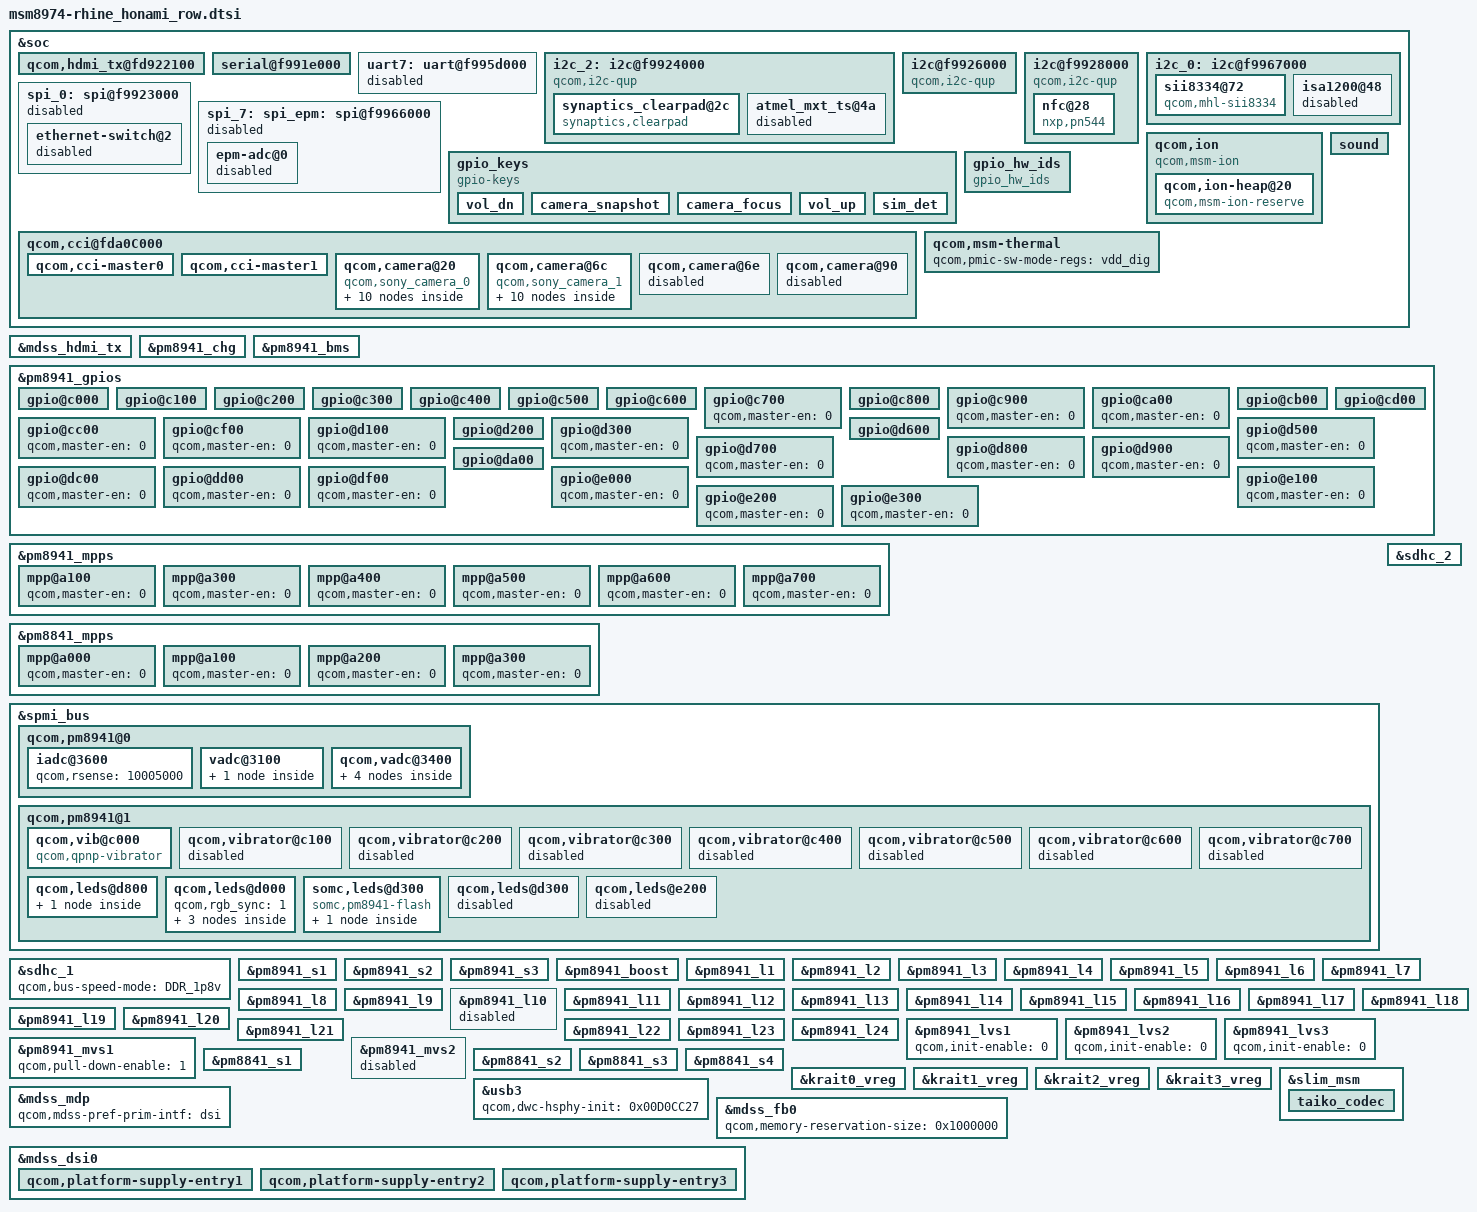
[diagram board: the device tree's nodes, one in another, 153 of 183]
/* arch/arm/boot/dts/msm8974-rhine_honami_row.dtsi
 *
 * Copyright (C) 2013-2014 Sony Mobile Communications AB.
 *
 * Author: Kouhei Fujiya <Kouhei.X.Fujiya@sonymobile.com>
 *
 * This program is free software; you can redistribute it and/or modify
 * it under the terms of the GNU General Public License version 2 and
 * only version 2 as published by the Free Software Foundation.
 *
 * This program is distributed in the hope that it will be useful,
 * but WITHOUT ANY WARRANTY; without even the implied warranty of
 * MERCHANTABILITY or FITNESS FOR A PARTICULAR PURPOSE.  See the
 * GNU General Public License for more details.
 */

/include/ "dsi-panel-honami.dtsi"

&soc {
	qcom,hdmi_tx@fd922100 {
		status = "ok";
	};

	/* BLSP2 */
	serial@f991e000 {
		status = "ok";
	};

	/* BLSP7 */
	uart7: uart@f995d000 {
		status = "disabled";
	};

	/* BLSP2 */
	i2c_2: i2c@f9924000 {
		cell-index = <0>;
		compatible = "qcom,i2c-qup";
		qcom,i2c-bus-freq = <355000>;
		qcom,scl-gpio = <&msmgpio 7 0x00>;
		qcom,sda-gpio = <&msmgpio 6 0x00>;
		status = "ok";
		synaptics_clearpad@2c {
			compatible = "synaptics,clearpad";
			reg = <0x2c>;
			interrupt-parent = <&msmgpio>;
			interrupts = <61 0x2>;
			touch_vdd-supply = <&pm8941_l22>;
			touch_vio-supply = <&pm8941_s3>;
			synaptics,irq_gpio = <&msmgpio 61 0x00>;
			num_sensor_rx = <28>;
			num_sensor_tx = <15>;
			pen_enabled = <0>;
			touch_pressure_enabled = <1>;
			touch_size_enabled = <0>;
			touch_orientation_enabled = <0>;
			preset_x_max = <1079>;
			preset_y_max = <1919>;
			preset_n_fingers = <10>;
			preset_n_bytes_per_object = <8>;
			por_delay_after = <200>;
		};

		atmel_mxt_ts@4a {
			status = "disabled";
		};
	};

	/* BLSP4 */
	i2c@f9926000 {
		cell-index = <1>;
		compatible = "qcom,i2c-qup";
		reg = <0xf9926000 0x1000>;
		#address-cells = <1>;
		#size-cells = <0>;
		reg-names = "qup_phys_addr";
		interrupts = <0 98 0>;
		interrupt-names = "qup_err_intr";
		qcom,i2c-bus-freq = <355000>;
		qcom,i2c-src-freq = <50000000>;
		qcom,master-id = <86>;
		status = "ok";
	};

	/* BLSP6 */
	i2c@f9928000 {
		cell-index = <2>;
		compatible = "qcom,i2c-qup";
		reg = <0xf9928000 0x1000>;
		#address-cells = <1>;
		#size-cells = <0>;
		reg-names = "qup_phys_addr";
		interrupts = <0 100 0>;
		interrupt-names = "qup_err_intr";
		qcom,i2c-bus-freq = <355000>;
		qcom,i2c-src-freq = <50000000>;
		qcom,master-id = <86>;
		status = "ok";
		nfc@28 {
			compatible = "nxp,pn544";
			reg = <0x28>;
			interrupt-parent = <&msmgpio>;
			interrupts = <59 0x0>;
			nxp,pvdd_en = <&msmgpio 76 0x00>;
			nxp,irq_gpio = <&msmgpio 59 0x00>;
			nxp,dwld_en = <&msmgpio 77 0x00>;
			nxp,ven = <&pm8941_gpios 23 0x01>;
			gpio_fwdl_enable = <0 0 0 2>;
			gpio_fwdl_disable = <0 0 1 0>;
		};
	};

	/* BLSP11 */
	i2c_0: i2c@f9967000 {
		cell-index = <4>;
		qcom,i2c-bus-freq = <355000>;
		status = "ok";
		sii8334@72 {
			compatible = "qcom,mhl-sii8334";
			reg = <0x72>;
			interrupt-parent = <&msmgpio>;
			interrupts = <64 0x2008>;
			mhl-intr-gpio = <&msmgpio 64 0>;
			mhl-pwr-gpio = <&msmgpio 60 0>;
			mhl-rst-gpio = <&msmgpio 16 0>;
			qcom,hdmi-tx-map = <&mdss_hdmi_tx>;
		};

		isa1200@48 {
			status = "disabled";
		};
	};

	/* BLSP1 */
	spi_0: spi@f9923000 {
		status = "disabled";

		ethernet-switch@2 {
			status = "disabled";
		};
	};

	/* BLSP10 */
	spi_7: spi_epm: spi@f9966000 {
		status = "disabled";

		epm-adc@0 {
			status = "disabled";
		};
	};

	gpio_keys {
		compatible = "gpio-keys";
		input-name = "gpio-keys";
		interrupt-parent = <&msmgpio>;
		interrupts = <9 0>;

		vol_dn {
			label = "volume_down";
			gpios = <&pm8941_gpios 2 0x1>;
			linux,input-type = <1>;
			linux,code = <114>;
			gpio-key,wakeup;
			debounce-interval = <15>;
		};

		camera_snapshot {
			label = "camera_snapshot";
			gpios = <&pm8941_gpios 3 0x1>;
			linux,input-type = <1>;
			linux,code = <0x2fe>;
			gpio-key,wakeup;
			debounce-interval = <15>;
		};

		camera_focus {
			label = "camera_focus";
			gpios = <&pm8941_gpios 4 0x1>;
			linux,input-type = <1>;
			linux,code = <0x210>;
			gpio-key,wakeup;
			debounce-interval = <15>;
		};

		vol_up {
			label = "volume_up";
			gpios = <&pm8941_gpios 5 0x1>;
			linux,input-type = <1>;
			linux,code = <115>;
			gpio-key,wakeup;
			debounce-interval = <15>;
		};

		sim_det {
			label = "sim-detection";
			gpios = <&msmgpio 9 0x0>;
			linux,input-type = <5>;
			linux,code = <7>;
			gpio-key,wakeup;
			debounce-interval = <10>;
		};
	};

	qcom,cci@fda0C000 {
		qcom,cci-master0 {
			qcom,hw-thigh = <22>;
			qcom,hw-tlow = <33>;
		};

		qcom,cci-master1 {
			qcom,hw-thigh = <22>;
			qcom,hw-tlow = <33>;
		};

		qcom,camera@20 {
			compatible = "qcom,sony_camera_0";
			reg = <0x20 0x0>;
			status = "ok";
			qcom,slave-id = <0x20 0x0 0x0000>;
			qcom,csiphy-sd-index = <0>;
			qcom,csid-sd-index = <0>;
			qcom,mount-angle = <270>;
			qcom,sensor-name = "sony_camera_0";
			cam_vdig-supply = <&pm8941_l3>;
			cam_vana-supply = <&pm8941_l17>;
			cam_vio-supply = <&pm8941_lvs2>;
			cam_vaf-supply = <&pm8941_l23>;
			qcom,cam-vreg-name = "cam_vdig", "cam_vana", "cam_vio",
					     "cam_vaf";
			qcom,cam-vreg-type = <0 0 1 0>;
			qcom,cam-vreg-min-voltage = <1200000 2700000 0 2800000>;
			qcom,cam-vreg-max-voltage = <1200000 2700000 0 2800000>;
			qcom,cam-vreg-op-mode = <105000 85600 0 300000>;
			qcom,gpio-no-mux = <0>;
			gpios = <&msmgpio 15 0>,
				<&msmgpio 94 0>;
			qcom,gpio-reset = <1>;
			qcom,gpio-req-tbl-num = <0 1>;
			qcom,gpio-req-tbl-flags = <1 0>;
			qcom,gpio-req-tbl-label = "CAMIF_MCLK",
						  "CAM_RESET1";
			qcom,gpio-set-tbl-num = <1 1>;
			qcom,gpio-set-tbl-flags = <0 2>;
			qcom,gpio-set-tbl-delay = <1 1000>;
			qcom,csi-lane-assign = <0x4320>;
			qcom,csi-lane-mask = <0x1F>;
			qcom,sensor-position = <0>;
			qcom,sensor-mode = <1>;
			qcom,cci-master = <0>;
			sony,i2c_addr = <0x20>;
			sony,eeprom_addr = <0xA0>;
			sony,eeprom_type = <0>;
			sony,eeprom_max_len = <2048>;
			sony,gpio_af = <0>;
			sony,subdev_code = <0x3007>;

			sony,camera_modules {
				module_names = "GENERIC", "SOI20BS0",
						"SOI08BS2";
				default_module_name = "SOI20BS0";

				GENERIC {
					mount_angle = <270>;
					sensor_rotation = <180>;
					sensor_facing = <0>;
					has_3a = <0>;
					pll_num = <18>;
					pll = <600 318 386 684 318 578 293 600 597 599 318 596 599 474 599 825 578 578>;
					power_off {
						commands =
								"I2C_WRITE",
								"GPIO_RESET",
								"CAM_CLK",
								"CAM_VAF",
								"CAM_VANA",
								"CAM_VIO",
								"CAM_VDIG",
								"EXIT";
						CAM_VDIG =
							<0 0xFFFFFFFF 0 15>;
						CAM_VIO = <1 0xFFFFFFFF 0 1>;
						CAM_VANA =
							<2 0xFFFFFFFF 0 1>;
						CAM_VAF = <3 0xFFFFFFFF 0 0>;
						GPIO_RESET = <5 0x0 0 1>;
						CAM_CLK = <6 0xFFFFFFFF 0 1>;
						I2C_WRITE = <7 0x0100 0 100>;
						EXIT = <8 0x0 0 0>;
					};
					power_on {
						commands =
								"CAM_VDIG",
								"CAM_VIO",
								"CAM_VANA",
								"CAM_VAF",
								"GPIO_RESET",
								"CAM_CLK",
								"EXIT";
						CAM_VDIG = <0 1200 85000 1>;
						CAM_VIO = <1 0 0 1>;
						CAM_VANA = <2 2700 103000 0>;
						CAM_VAF = <3 2800 106500 2>;
						GPIO_RESET = <5 1 0 1>;
						CAM_CLK = <6 0 0 1>;
						EXIT = <8 0x0 0 0>;
					};
				};
				SOI20BS0 {
					mount_angle = <90>;
					sensor_rotation = <0>;
					sensor_facing = <0>;
					has_3a = <0>;
					pll_num = <18>;
					pll = <600 318 386 684 318 578 293 600 597 599 318 596 599 474 599 825 578 578>;
					power_off {
						commands =
								"I2C_WRITE",
								"GPIO_RESET",
								"CAM_CLK",
								"CAM_VAF",
								"CAM_VANA",
								"CAM_VIO",
								"CAM_VDIG",
								"EXIT";
						CAM_VDIG =
							<0 0xFFFFFFFF 0 15>;
						CAM_VIO = <1 0xFFFFFFFF 0 1>;
						CAM_VANA =
							<2 0xFFFFFFFF 0 1>;
						CAM_VAF = <3 0xFFFFFFFF 0 0>;
						GPIO_RESET = <5 0x0 0 1>;
						CAM_CLK = <6 0xFFFFFFFF 0 1>;
						I2C_WRITE = <7 0x0100 0 100>;
						EXIT = <8 0x0 0 0>;
					};
					power_on {
						commands =
								"CAM_VDIG",
								"CAM_VIO",
								"CAM_VANA",
								"CAM_VAF",
								"GPIO_RESET",
								"CAM_CLK",
								"EXIT";
						CAM_VDIG = <0 1200 85000 1>;
						CAM_VIO = <1 0 0 1>;
						CAM_VANA = <2 2700 103000 0>;
						CAM_VAF = <3 2800 106500 2>;
						GPIO_RESET = <5 1 0 1>;
						CAM_CLK = <6 0 0 1>;
						EXIT = <8 0x0 0 0>;
					};
				};
				SOI08BS2 {
					mount_angle = <270>;
					sensor_rotation = <180>;
					sensor_facing = <0>;
					has_3a = <0>;
					pll_num = <18>;
					pll = <674 674 674 674 674 674 674 674 674 674 674 674 674 674 674 674 674 674>;
					power_off {
						commands =
								"I2C_WRITE",
								"GPIO_RESET",
								"CAM_CLK",
								"CAM_VAF",
								"CAM_VANA",
								"CAM_VIO",
								"CAM_VDIG",
								"EXIT";
						CAM_VDIG =
							<0 0xFFFFFFFF 0 15>;
						CAM_VIO = <1 0xFFFFFFFF 0 1>;
						CAM_VANA =
							<2 0xFFFFFFFF 0 1>;
						CAM_VAF = <3 0xFFFFFFFF 0 0>;
						GPIO_RESET = <5 0x0 0 1>;
						CAM_CLK = <6 0xFFFFFFFF 0 1>;
						I2C_WRITE = <7 0x0100 0 100>;
						EXIT = <8 0x0 0 0>;
					};
					power_on {
						commands =
								"CAM_VDIG",
								"CAM_VIO",
								"CAM_VANA",
								"CAM_VAF",
								"GPIO_RESET",
								"CAM_CLK",
								"EXIT";
						CAM_VDIG = <0 1200 85000 1>;
						CAM_VIO = <1 0 0 1>;
						CAM_VANA = <2 2700 103000 0>;
						CAM_VAF = <3 2800 106500 2>;
						GPIO_RESET = <5 1 0 1>;
						CAM_CLK = <6 0 0 1>;
						EXIT = <8 0x0 0 0>;
					};
				};
			};
		};

		qcom,camera@6c {
			compatible = "qcom,sony_camera_1";
			reg = <0x6c 0x0>;
			status = "ok";
			qcom,slave-id = <0x6c 0x0000 0x0000>;
			qcom,csiphy-sd-index = <2>;
			qcom,csid-sd-index = <2>;
			qcom,mount-angle = <270>;
			qcom,sensor-name = "sony_camera_1";
			cam_vdig-supply = <&pm8941_l3>;
			cam_vana-supply = <&pm8941_l17>;
			cam_vio-supply = <&pm8941_lvs2>;
			qcom,cam-vreg-name = "cam_vdig", "cam_vana", "cam_vio";
			qcom,cam-vreg-type = <0 0 1>;
			qcom,cam-vreg-min-voltage = <1200000 2700000 0>;
			qcom,cam-vreg-max-voltage = <1200000 2700000 0>;
			qcom,cam-vreg-op-mode = <105000 85600 0>;
			qcom,gpio-no-mux = <0>;
			gpios = <&msmgpio 17 0>,
				<&msmgpio 18 0>;
			qcom,gpio-reset = <1>;
			qcom,gpio-req-tbl-num = <0 1>;
			qcom,gpio-req-tbl-flags = <1 0>;
			qcom,gpio-req-tbl-label = "CAMIF_MCLK",
						  "CAM_RESET1";
			qcom,gpio-set-tbl-num = <1 1>;
			qcom,gpio-set-tbl-flags = <0 2>;
			qcom,gpio-set-tbl-delay = <1 1000>;
			qcom,csi-lane-assign = <0x4320>;
			qcom,csi-lane-mask = <0x7>;
			qcom,sensor-position = <1>;
			qcom,sensor-mode = <1>;
			qcom,cci-master = <1>;
			sony,i2c_addr = <0x6c>;
			sony,eeprom_addr = <0xA0>;
			sony,eeprom_type = <0>;
			sony,eeprom_max_len = <1024>;
			sony,gpio_af = <0>;
			sony,subdev_code = <0x3007>;

			sony,camera_modules {
				module_names = "GENERIC", "LGI02BN1",
						"SEM02BN1";
				default_module_name = "SEM02BN1";

				GENERIC {
					mount_angle = <270>;
					sensor_rotation = <180>;
					sensor_facing = <1>;
					has_3a = <0>;
					pll_num = <18>;
					pll = <101 101 101 101 101 101 101 101 101 101 101 101 101 101 101 101 101 101>;
					power_off {
						commands =
								"I2C_WRITE",
								"GPIO_RESET",
								"CAM_CLK",
								"CAM_VANA",
								"CAM_VIO",
								"CAM_VDIG",
								"EXIT";
						CAM_VDIG =
							<0 0xFFFFFFFF 0 1>;
						CAM_VIO = <1 0xFFFFFFFF 0 1>;
						CAM_VANA =
							<2 0xFFFFFFFF 0 1>;
						GPIO_RESET = <5 0x0 0 1>;
						CAM_CLK = <6 0xFFFFFFFF 0 1>;
						I2C_WRITE = <7 0x0100 0 100>;
						EXIT = <8 0x0 0 0>;
					};
					power_on {
						commands =
								"CAM_VDIG",
								"CAM_VIO",
								"CAM_VANA",
								"GPIO_RESET",
								"CAM_CLK",
								"EXIT";
						CAM_VDIG = <0 1200 85000 1>;
						CAM_VIO = <1 0 0 1>;
						CAM_VANA = <2 2700 103000 1>;
						GPIO_RESET = <5 1 0 1>;
						CAM_CLK = <6 0 0 1>;
						EXIT = <8 0x0 0 0>;
					};
				};
				LGI02BN1 {
					mount_angle = <270>;
					sensor_rotation = <180>;
					sensor_facing = <1>;
					has_3a = <0>;
					pll_num = <18>;
					pll = <101 101 101 101 101 101 101 101 101 101 101 101 101 101 101 101 101 101>;
					power_off {
						commands =
								"I2C_WRITE",
								"GPIO_RESET",
								"CAM_CLK",
								"CAM_VANA",
								"CAM_VIO",
								"CAM_VDIG",
								"EXIT";
						CAM_VDIG =
							<0 0xFFFFFFFF 0 1>;
						CAM_VIO = <1 0xFFFFFFFF 0 1>;
						CAM_VANA =
							<2 0xFFFFFFFF 0 1>;
						GPIO_RESET = <5 0x0 0 1>;
						CAM_CLK = <6 0xFFFFFFFF 0 1>;
						I2C_WRITE = <7 0x0100 0 100>;
						EXIT = <8 0x0 0 0>;
					};
					power_on {
						commands =
								"CAM_VDIG",
								"CAM_VIO",
								"CAM_VANA",
								"GPIO_RESET",
								"CAM_CLK",
								"EXIT";
						CAM_VDIG = <0 1200 85000 1>;
						CAM_VIO = <1 0 0 1>;
						CAM_VANA = <2 2700 103000 1>;
						GPIO_RESET = <5 1 0 1>;
						CAM_CLK = <6 0 0 1>;
						EXIT = <8 0x0 0 0>;
					};
				};
				SEM02BN1 {
					mount_angle = <270>;
					sensor_rotation = <180>;
					sensor_facing = <1>;
					has_3a = <0>;
					pll_num = <18>;
					pll = <101 101 101 101 101 101 101 101 101 101 101 101 101 101 101 101 101 101>;
					power_off {
						commands =
								"I2C_WRITE",
								"GPIO_RESET",
								"CAM_CLK",
								"CAM_VANA",
								"CAM_VIO",
								"CAM_VDIG",
								"EXIT";
						CAM_VDIG =
							<0 0xFFFFFFFF 0 1>;
						CAM_VIO = <1 0xFFFFFFFF 0 1>;
						CAM_VANA =
							<2 0xFFFFFFFF 0 1>;
						GPIO_RESET = <5 0x0 0 1>;
						CAM_CLK = <6 0xFFFFFFFF 0 1>;
						I2C_WRITE = <7 0x0100 0 100>;
						EXIT = <8 0x0 0 0>;
					};
					power_on {
						commands =
								"CAM_VDIG",
								"CAM_VIO",
								"CAM_VANA",
								"GPIO_RESET",
								"CAM_CLK",
								"EXIT";
						CAM_VDIG = <0 1200 85000 1>;
						CAM_VIO = <1 0 0 1>;
						CAM_VANA = <2 2700 103000 1>;
						GPIO_RESET = <5 1 0 1>;
						CAM_CLK = <6 0 0 1>;
						EXIT = <8 0x0 0 0>;
					};
				};
			};
		};

		/* disable Qualcomm camera sensors */
		qcom,camera@6e {
			status = "disabled";
		};

		qcom,camera@90 {
			status = "disabled";
		};
	};

	qcom,ion {
		compatible = "qcom,msm-ion";

		qcom,ion-heap@20 { /* CAMERA HEAP */
			compatible = "qcom,msm-ion-reserve";
			reg = <20>;
			qcom,heap-align = <0x1000>;
			qcom,memory-reservation-type = "EBI1"; /* reserve EBI memory */
			qcom,memory-reservation-size = <0x6400000>;
			qcom,ion-heap-type = "CARVEOUT";
		};
	};

	sound {
		qcom,audio-routing =
			"RX_BIAS", "MCLK",
			"LDO_H", "MCLK",
			"Ext Spk Bottom Pos", "LINEOUT1",
			"Ext Spk Bottom Neg", "LINEOUT3",
			"Ext Spk Top Pos", "LINEOUT2",
			"Ext Spk Top Neg", "LINEOUT4",
			"AMIC1", "MIC BIAS1 External",
			"MIC BIAS1 External", "Handset Mic",
			"AMIC2", "MIC BIAS2 External",
			"MIC BIAS2 External", "Headset Mic",
			"AMIC3", "MIC BIAS3 External",
			"MIC BIAS3 External", "ANCLeft Headset Mic",
			"AMIC4", "MIC BIAS1 External",
			"MIC BIAS1 External", "Handset Mic",
			"AMIC5", "MIC BIAS1 External",
			"MIC BIAS1 External", "Secondary Mic",
			"AMIC6", "MIC BIAS4 External",
			"MIC BIAS4 External", "Handset FB ANC Mic";
	};

	gpio_hw_ids {
		compatible = "gpio_hw_ids";

		gpios = <&pm8941_gpios 1 0>,
			<&pm8941_gpios 6 0>,
			<&pm8941_gpios 7 0>,
			<&pm8941_gpios 14 0>;
	};

	qcom,msm-thermal {
		qcom,pmic-sw-mode-regs = "vdd_dig";
	};
};

&mdss_hdmi_tx {
	/* rhine doesn't use hpd-5v */
	qcom,hdmi-tx-supply-names = "hpd-gdsc", "core-vdda", "core-vcc";
	qcom,hdmi-tx-min-voltage-level = <0 1800000 1800000>;
	qcom,hdmi-tx-max-voltage-level = <0 1800000 1800000>;
	qcom,hdmi-tx-peak-current = <0 300000 0>;
};

&pm8941_chg {
	qcom,vddmax-mv = <4350>;
	qcom,vddsafe-mv = <4400>;
	qcom,ibatmax-ma = <1500>;
	qcom,ibatterm-ma = <150>;
	qcom,ibatsafe-ma = <1500>;
	qcom,maxinput-dc-ma = <1800>;
	qcom,maxinput-usb-ma = <1500>;
	qcom,cool-bat-mv = <4350>;
	qcom,ibatmax-warm-ma = <900>;
	qcom,warm-bat-mv = <4200>;
	qcom,ibatmax-cool-ma = <900>;
	qcom,vbatdet-delta-mv = <20>;
	qcom,vbatdet-delta-soc = <1>;
	qcom,thermal-mitigation = <1500 1500 1100 900 700 500 300 200 100 0>;
	qcom,tchg-mins = <512>;
};

&pm8941_bms {
	qcom,r-sense-uohm = <10005>;
	qcom,v-cutoff-uv = <3200000>;
	qcom,max-voltage-uv = <4350000>;
	qcom,r-conn-mohm = <0>;
	qcom,low-soc-calculate-soc-threshold = <5>;
	qcom,low-soc-calculate-soc-ms = <1000>;
	qcom,calculate-soc-ms = <30000>;
	qcom,chg-term-ua = <150000>;
	qcom,use-external-rsense = <1>;
	qcom,batt-type = <3>;
	qcom,shutdown-soc-valid-limit = <40>;
	qcom,clamp-soc-max-count = <2>;
	qcom,fcc-resolution = <13>;
};

&pm8941_gpios {
	/* GPIO_1: HW_ID_0 */
	gpio@c000 {
		qcom,src-sel = <0>;		/* GPIO */
		qcom,mode = <0>;		/* In */
		qcom,vin-sel = <2>;		/* S3 */
		qcom,pull = <5>;		/* NP */
		qcom,master-en = <1>;		/* Enable */
		status = "ok";
	};

	/* GPIO_2: VOL_DN */
	gpio@c100 {
		qcom,src-sel = <0>;		/* GPIO */
		qcom,mode = <0>;		/* In */
		qcom,vin-sel = <2>;		/* S3 */
		qcom,pull = <0>;		/* PU */
		qcom,master-en = <1>;		/* Enable */
		status = "ok";
	};

	/* GPIO_3: SNAPSHOT */
	gpio@c200 {
		qcom,src-sel = <0>;		/* GPIO */
		qcom,mode = <0>;		/* In */
		qcom,vin-sel = <2>;		/* S3 */
		qcom,pull = <0>;		/* PU */
		qcom,master-en = <1>;		/* Enable */
		status = "ok";
	};

	/* GPIO_4: FOCUS */
	gpio@c300 {
		qcom,src-sel = <0>;		/* GPIO */
		qcom,mode = <0>;		/* In */
		qcom,vin-sel = <2>;		/* S3 */
		qcom,pull = <0>;		/* PU */
		qcom,master-en = <1>;		/* Enable */
		status = "ok";
	};

	/* GPIO_5: VOL_UP */
	gpio@c400 {
		qcom,src-sel = <0>;		/* GPIO */
		qcom,mode = <0>;		/* In */
		qcom,vin-sel = <2>;		/* S3 */
		qcom,pull = <0>;		/* PU */
		qcom,master-en = <1>;		/* Enable */
		status = "ok";
	};

	/* GPIO_6: HW_ID_1 */
	gpio@c500 {
		qcom,src-sel = <0>;		/* GPIO */
		qcom,mode = <0>;		/* In */
		qcom,vin-sel = <2>;		/* S3 */
		qcom,pull = <5>;		/* NP */
		qcom,master-en = <1>;		/* Enable */
		status = "ok";
	};

	/* GPIO_7: HW_ID_2 */
	gpio@c600 {
		qcom,src-sel = <0>;		/* GPIO */
		qcom,mode = <0>;		/* In */
		qcom,vin-sel = <2>;		/* S3 */
		qcom,pull = <5>;		/* NP */
		qcom,master-en = <1>;		/* Enable */
		status = "ok";
	};

	/* GPIO_8: NC */
	gpio@c700 {
		qcom,master-en = <0>;		/* Disable */
		status = "ok";
	};

	/* GPIO_9: RF_ID_EN */
	gpio@c800 {
		qcom,src-sel = <0>;		/* GPIO */
		qcom,mode = <1>;		/* Out */
		qcom,output-type = <0>;		/* CMOS */
		qcom,vin-sel = <2>;		/* S3 */
		qcom,out-strength = <3>;	/* High */
		qcom,invert = <0>;		/* Low */
		qcom,master-en = <1>;		/* Enable */
		status = "ok";
	};

	/* GPIO_10: NC (FCHG_CNT) */
	gpio@c900 {
		qcom,master-en = <0>;		/* Disable */
		status = "ok";
	};

	/* GPIO_11: NC (AUD_DSP_PWR_EN) */
	gpio@ca00 {
		qcom,master-en = <0>;		/* Disable */
		status = "ok";
	};

	/* GPIO_12: RF_ID_EXTENTION */
	gpio@cb00 {
		qcom,src-sel = <0>;		/* GPIO */
		qcom,mode = <0>;		/* In */
		qcom,vin-sel = <2>;		/* S3 */
		qcom,pull = <4>;		/* PD */
		qcom,master-en = <1>;		/* Enable */
		status = "ok";
	};

	/* GPIO_13: NC (TUNER_STATUS0) */
	gpio@cc00 {
		qcom,master-en = <0>;		/* Disable */
		status = "ok";
	};

	/* GPIO_14: HW_ID_3 */
	gpio@cd00 {
		qcom,src-sel = <0>;		/* GPIO */
		qcom,mode = <0>;		/* In */
		qcom,vin-sel = <2>;		/* S3 */
		qcom,pull = <4>;		/* PD */
		qcom,master-en = <1>;		/* Enable */
		status = "ok";
	};

	/* GPIO_15: DIVCLK1_CODEC */
	/* Follow QCT */

	/* GPIO_16: NC */
	gpio@cf00 {
		qcom,master-en = <0>;		/* Disable */
		status = "ok";
	};

	/* GPIO_17: (DIVCLK3) QPA_XO */
	/* Follow QCT */

	/* GPIO_18: NC (TUNER_STATUS1) */
	gpio@d100 {
		qcom,master-en = <0>;		/* Disable */
		status = "ok";
	};

	/* GPIO_19: DISP_RESET_N */
	gpio@d200 {
		qcom,src-sel = <0>;		/* GPIO */
		qcom,mode = <1>;		/* Out */
		qcom,output-type = <0>;		/* CMOS */
		qcom,vin-sel = <2>;		/* S3 */
		qcom,out-strength = <1>;	/* Low */
		qcom,invert = <0>;		/* Low */
		qcom,master-en = <1>;		/* Enable */
		status = "ok";
	};

	/* GPIO_20: NC (IR_LEVEL_EN) */
	gpio@d300 {
		qcom,master-en = <0>;		/* Disable */
		status = "ok";
	};

	/* GPIO_21: BOOST_BYP_EN */
	/* Follow QCT */

	/* GPIO_22: NC (HS_DET) */
	gpio@d500 {
		qcom,master-en = <0>;		/* Disable */
		status = "ok";
	};

	/* GPIO_23: NFC_VEN */
	gpio@d600 {
		qcom,src-sel = <0>;		/* GPIO */
		qcom,mode = <1>;		/* Out */
		qcom,output-type = <0>;		/* CMOS */
		qcom,vin-sel = <2>;		/* S3 */
		qcom,out-strength = <1>;	/* Low */
		qcom,invert = <1>;		/* High */
		qcom,master-en = <1>;		/* Enable */
		status = "ok";
	};

	/* GPIO_24: NC (NFC_EXT_LDO_EN) */
	gpio@d700 {
		qcom,master-en = <0>;		/* Disable */
		status = "ok";
	};

	/* GPIO_25: NC (IR_RESET) */
	gpio@d800 {
		qcom,master-en = <0>;		/* Disable */
		status = "ok";
	};

	/* GPIO_26: NC (TUNER_ANT_SW_EN) */
	gpio@d900 {
		qcom,master-en = <0>;		/* Disable */
		status = "ok";
	};

	/* GPIO_27: FLASH_LED_NOW */
	gpio@da00 {
		qcom,src-sel = <2>;		/* Alternate function 1 */
		qcom,mode = <0>;		/* In */
		qcom,vin-sel = <2>;		/* S3 */
		qcom,pull = <4>;		/* PD */
		qcom,master-en = <1>;		/* Enable */
		status = "ok";
	};

	/* GPIO_28: TX_GTR_THRES */
	/* Follow QCT */

	/* GPIO_29: NC */
	gpio@dc00 {
		qcom,master-en = <0>;		/* Disable */
		status = "ok";
	};

	/* GPIO_30: NC */
	gpio@dd00 {
		qcom,master-en = <0>;		/* Disable */
		status = "ok";
	};

	/* GPIO_31: BATT_REM_ALERM */
	/* Follow QCT */

	/* GPIO_32: NC (TUNER_ANT_SW1) */
	gpio@df00 {
		qcom,master-en = <0>;		/* Disable */
		status = "ok";
	};

	/* GPIO_33: NC (FELICA_FF) */
	gpio@e000 {
		qcom,master-en = <0>;		/* Disable */
		status = "ok";
	};

	/* GPIO_34: NC (FELICA_LOCK) */
	gpio@e100 {
		qcom,master-en = <0>;		/* Disable */
		status = "ok";
	};

	/* GPIO_35: NC (Reserved for ANC_HS_DET) */
	gpio@e200 {
		qcom,master-en = <0>;		/* Disable */
		status = "ok";
	};

	/* GPIO_36: NC */
	gpio@e300 {
		qcom,master-en = <0>;		/* Disable */
		status = "ok";
	};
};

&pm8941_mpps {
	/* MPP_1: SDC_UIM_VBIAS */
	/* Follow QCT */

	/* MPP_2: NC */
	mpp@a100 {
		qcom,master-en = <0>;		/* Disable */
		status = "ok";
	};

	/* MPP_3: TXDAC0_VREF */
	/* Follow QCT */

	/* MPP_4: NC */
	mpp@a300 {
		qcom,master-en = <0>;		/* Disable */
		status = "ok";
	};

	/* MPP_5: NC */
	mpp@a400 {
		qcom,master-en = <0>;		/* Disable */
		status = "ok";
	};

	/* MPP_6: NC (ACC_ADC) */
	mpp@a500 {
		qcom,master-en = <0>;		/* Disable */
		status = "ok";
	};

	/* MPP_7: RF_ID */
	mpp@a600 {
		qcom,master-en = <0>;		/* Disable */
		status = "ok";
	};

	/* MPP_8: NC */
	mpp@a700 {
		qcom,master-en = <0>;		/* Disable */
		status = "ok";
	};
};

&pm8841_mpps {
	/* MPP_1: NC (LMU_EN) */
	mpp@a000 {
		qcom,master-en = <0>;		/* Disable */
		status = "ok";
	};

	/* MPP_2: NC (FLASH_DR_RST_N) */
	mpp@a100 {
		qcom,master-en = <0>;		/* Disable */
		status = "ok";
	};

	/* MPP_3: NC */
	mpp@a200 {
		qcom,master-en = <0>;		/* Disable */
		status = "ok";
	};

	/* MPP_4: NC */
	mpp@a300 {
		qcom,master-en = <0>;		/* Disable */
		status = "ok";
	};
};

&spmi_bus {
	qcom,pm8941@0 {
		iadc@3600 {
			qcom,rsense = <10005000>;
		};
	};

	qcom,pm8941@1 {
		qcom,vib@c000 {
			status = "okay";
			compatible = "qcom,qpnp-vibrator";
			reg = <0xc000 0x100>;
			label = "vibrator";
			qcom,qpnp-vib-vtg-level-mV = <3100>;
		};

		qcom,vibrator@c100 {
			status = "disabled";
		};

		qcom,vibrator@c200 {
			status = "disabled";
		};

		qcom,vibrator@c300 {
			status = "disabled";
		};

		qcom,vibrator@c400 {
			status = "disabled";
		};

		qcom,vibrator@c500 {
			status = "disabled";
		};

		qcom,vibrator@c600 {
			status = "disabled";
		};

		qcom,vibrator@c700 {
			status = "disabled";
		};

		qcom,leds@d800 {
			status = "okay";
			qcom,wled_0 {
				label = "wled";
				linux,name = "wled:backlight";
				linux,default-trigger = "bkl-trigger";
				qcom,cs-out-en = <1>;
				qcom,cabc-en = <1>;
				qcom,op-fdbck = <0>;
				qcom,default-state = "on";
				qcom,max-current = <20>;
				qcom,ctrl-delay-us = <0>;
				qcom,boost-curr-lim = <3>;
				qcom,cp-sel = <0>;
				qcom,switch-freq = <2>;
				qcom,ovp-val = <2>;
				qcom,num-strings = <2>;
				qcom,id = <0>;
			};
		};

		qcom,leds@d000 {
			status = "okay";
			qcom,rgb_sync = <1>;

			qcom,rgb_0 {
				label = "rgb";
				linux,name = "led:rgb_red";
				qcom,mode = "pwm";
				qcom,pwm-channel = <6>;
				qcom,pwm-us = <1000>;
				qcom,pwm-max-value = <304>;
				qcom,max-current = <12>;
				qcom,default-state = "off";
				qcom,id = <3>;
				linux,default-trigger = "none";
			};

			qcom,rgb_1 {
				label = "rgb";
				linux,name = "led:rgb_green";
				qcom,mode = "pwm";
				qcom,pwm-channel = <5>;
				qcom,pwm-us = <1000>;
				qcom,pwm-max-value = <511>;
				qcom,max-current = <12>;
				qcom,default-state = "off";
				qcom,id = <4>;
				linux,default-trigger = "none";
			};

			qcom,rgb_2 {
				label = "rgb";
				linux,name = "led:rgb_blue";
				qcom,mode = "pwm";
				qcom,pwm-channel = <4>;
				qcom,pwm-us = <1000>;
				qcom,pwm-max-value = <368>;
				qcom,max-current = <12>;
				qcom,default-state = "off";
				qcom,id = <5>;
				linux,default-trigger = "none";
			};
		};

		somc,leds@d300 {
			status = "okay";
			compatible = "somc,pm8941-flash";
			reg = <0xd300 0x100>;
			label = "flash";
			torch-supply = <&pm8941_boost>;
			flash-supply = <&pm8941_chg_boost>;
			somc,headroom = <2>;
			somc,clamp-curr-mA = <13>;
			somc,startup-dly = <3>;
			somc,hw-strobe-config = <3>;
			somc,mask-enable = <1>;
			somc,vph-pwr-droop {
				somc,enable = <0>;
				somc,threshold = <0>;
				somc,debounce-time = <2>;
			};
		};

		qcom,leds@d300 {
			status = "disabled";
		};

		qcom,leds@e200 {
			status = "disabled";
		};
	};
};

&sdhc_1 {
	qcom,bus-speed-mode = "DDR_1p8v";
};

&sdhc_2 {
	qcom,pad-drv-on = <0x4 0x2 0x2>; /* 10mA, 6mA, 6mA */
	qcom,vdd-current-level = <400000 400000>;
};

/* Regulator config */
&pm8941_s1 {
	status = "ok";
};

&pm8941_s2 {
	status = "ok";
};

&pm8941_s3 {
	status = "ok";
};

&pm8941_boost { /* VREG_5V */
	regulator-min-microvolt = <5100000>;
	regulator-max-microvolt = <5100000>;
	status = "ok";
};

&pm8941_l1 {
	status = "ok";
};

&pm8941_l2 {
	status = "ok";
};

&pm8941_l3 {
	regulator-min-microvolt = <1200000>;
	regulator-max-microvolt = <1200000>;
	qcom,init-enable = <0>;
	qcom,init-voltage = <1200000>;
	status = "ok";
};

&pm8941_l4 {
	status = "ok";
};

&pm8941_l5 {
	status = "ok";
};

&pm8941_l6 {
	status = "ok";
};

&pm8941_l7 {
	status = "ok";
};

&pm8941_l8 {
	status = "ok";
};

&pm8941_l9 {
	status = "ok";
};

&pm8941_l10 {
	status = "disabled";
};

&pm8941_l11 {
	status = "ok";
};

&pm8941_l12 {
	status = "ok";
};

&pm8941_l13 {
	status = "ok";
};

&pm8941_l14 {
	status = "ok";
};

&pm8941_l15 {
	status = "ok";
};

&pm8941_l16 {
	status = "ok";
};

&pm8941_l17 {
	regulator-min-microvolt = <2700000>;
	regulator-max-microvolt = <2700000>;
	qcom,init-enable = <0>;
	qcom,init-voltage = <2700000>;
	status = "ok";
};

&pm8941_l18 {
	regulator-min-microvolt = <2850000>;
	regulator-max-microvolt = <2850000>;
	qcom,init-enable = <0>;
	qcom,init-voltage = <2850000>;
	status = "ok";
};

&pm8941_l19 {
	regulator-min-microvolt = <3300000>;
	regulator-max-microvolt = <3300000>;
	qcom,init-voltage = <3300000>;
	status = "ok";
};

&pm8941_l20 {
	regulator-min-microvolt = <2950000>;
	regulator-max-microvolt = <2950000>;
	qcom,init-voltage = <2950000>;
	status = "ok";
};

&pm8941_l21 {
	regulator-min-microvolt = <2950000>;
	regulator-max-microvolt = <2950000>;
	qcom,init-voltage = <2950000>;
	status = "ok";
};

&pm8941_l22 {
	regulator-min-microvolt = <3000000>;
	regulator-max-microvolt = <3000000>;
	qcom,init-enable = <0>;
	qcom,init-voltage = <3000000>;
	status = "ok";
};

&pm8941_l23 {
	regulator-min-microvolt = <2800000>;
	regulator-max-microvolt = <2800000>;
	qcom,init-enable = <0>;
	qcom,init-voltage = <2800000>;
	status = "ok";
};

&pm8941_l24 {
	status = "ok";
};

&pm8941_lvs1 {
	qcom,init-enable = <0>;
	status = "ok";
};

&pm8941_lvs2 {
	qcom,init-enable = <0>;
	status = "ok";
};

&pm8941_lvs3 {
	qcom,init-enable = <0>;
	status = "ok";
};

&pm8941_mvs1 { /* VREG_OTG */
	qcom,pull-down-enable = <1>;
	status = "ok";
};

&pm8941_mvs2 { /* VREG_HDMI */
	status = "disabled";
};

&pm8841_s1 {
	status = "ok";
};

&pm8841_s2 {
	status = "ok";
};

&pm8841_s3 {
	status = "ok";
};

&pm8841_s4 {
	status = "ok";
};

&krait0_vreg { /* PM8821 VREG_S5 */
	status = "ok";
};

&krait1_vreg { /* PM8821 VREG_S6 */
	status = "ok";
};

&krait2_vreg { /* PM8821 VREG_S7 */
	status = "ok";
};

&krait3_vreg { /* PM8821 VREG_S8 */
	status = "ok";
};

&slim_msm {
	taiko_codec {
		qcom,cdc-micbias-ldoh-v = <0x3>;
		qcom,cdc-micbias-cfilt1-mv = <2700>;
		qcom,cdc-micbias-cfilt2-mv = <2700>;
		qcom,cdc-micbias-cfilt3-mv = <2700>;
		qcom,cdc-micbias1-cfilt-sel = <0x1>;
		qcom,cdc-micbias2-cfilt-sel = <0x1>;
		qcom,cdc-micbias3-cfilt-sel = <0x1>;
		qcom,cdc-micbias4-cfilt-sel = <0x1>;
		qcom,cdc-micbias2-headset-only;
	};
};

&usb3 {
	qcom,dwc-hsphy-init = <0x00D0CC27>;
};

&spmi_bus {
	qcom,pm8941@0 {
		vadc@3100 {
			chan@b4 {
				qcom,scale-function = <8>;
			};
		};

		qcom,vadc@3400 {
			chan@30 {
				qcom,hw-settle-time = <15>;
			};

			chan@8 {
				qcom,hw-settle-time = <15>;
			};

			chan@6 {
				qcom,hw-settle-time = <15>;
			};

			chan@b4 {
				qcom,scale-function = <4>;
			};
		};
	};
};

&mdss_mdp {
	qcom,mdss-pref-prim-intf = "dsi";
};

&mdss_fb0 {
	qcom,memory-reservation-size = <0x1000000>; /* size 16MB */
};

&mdss_dsi0 {
	qcom,dsi-pref-prim-pan = <&dsi_renesas_default>;
	vdd-supply = <&pm8941_lvs3>;
	qcom,platform-enable-gpio = <&msmgpio 46 1>;
	qcom,platform-lane-config = [];
	qcom,platform-supply-entry1 {
			qcom,supply-name = "vdd";
			qcom,supply-min-voltage = <0>;
			qcom,supply-max-voltage = <0>;
			qcom,supply-enable-load = <100000>;
			qcom,supply-disable-load = <100>;
			qcom,supply-pre-on-sleep = <0>;
			qcom,supply-post-on-sleep = <0>;
			qcom,supply-pre-off-sleep = <0>;
			qcom,supply-post-off-sleep = <0>;
	};
	qcom,platform-supply-entry2 {
			qcom,supply-name = "vddio";
			qcom,supply-min-voltage = <1800000>;
			qcom,supply-max-voltage = <1800000>;
			qcom,supply-enable-load = <100000>;
			qcom,supply-disable-load = <100>;
			qcom,supply-pre-on-sleep = <0>;
			qcom,supply-post-on-sleep = <0>;
			qcom,supply-pre-off-sleep = <0>;
			qcom,supply-post-off-sleep = <0>;
	};
	qcom,platform-supply-entry3 {
			qcom,supply-name = "vdda";
			qcom,supply-min-voltage = <1200000>;
			qcom,supply-max-voltage = <1200000>;
			qcom,supply-enable-load = <100000>;
			qcom,supply-disable-load = <100>;
			qcom,supply-pre-on-sleep = <0>;
			qcom,supply-post-on-sleep = <0>;
			qcom,supply-pre-off-sleep = <0>;
			qcom,supply-post-off-sleep = <0>;
	};
};
